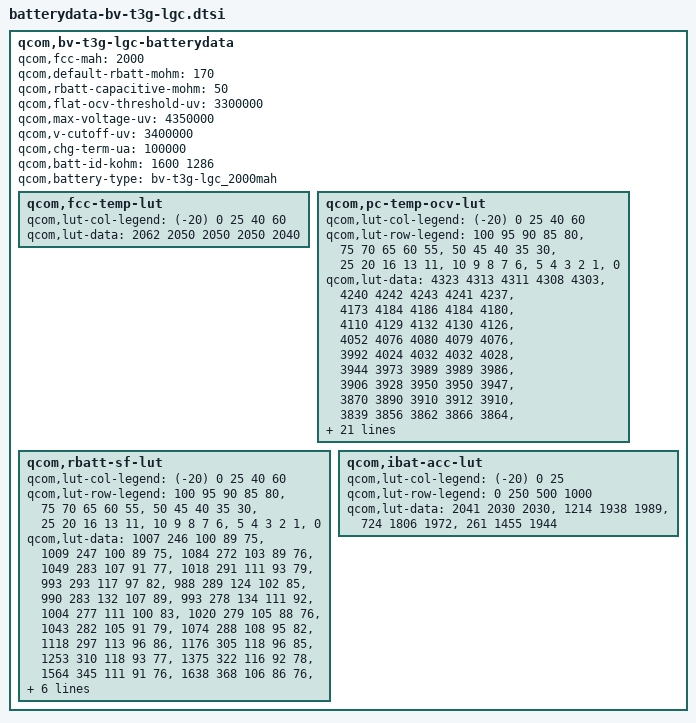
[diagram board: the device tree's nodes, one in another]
/* Copyright (c) 2013-2014, The Linux Foundation. All rights reserved.
 *
 * This program is free software; you can redistribute it and/or modify
 * it under the terms of the GNU General Public License version 2 and
 * only version 2 as published by the Free Software Foundation.
 *
 * This program is distributed in the hope that it will be useful,
 * but WITHOUT ANY WARRANTY; without even the implied warranty of
 * MERCHANTABILITY or FITNESS FOR A PARTICULAR PURPOSE.  See the
 * GNU General Public License for more details.
 */

qcom,bv-t3g-lgc-batterydata {
	qcom,fcc-mah = <2000>;
	qcom,default-rbatt-mohm = <170>;
	qcom,rbatt-capacitive-mohm = <50>;
	qcom,flat-ocv-threshold-uv = <3300000>;
	qcom,max-voltage-uv = <4350000>;
	qcom,v-cutoff-uv = <3400000>;
	qcom,chg-term-ua = <100000>;
	qcom,batt-id-kohm = <1600 1286>;
	qcom,battery-type = "bv-t3g-lgc_2000mah";

	qcom,fcc-temp-lut {
		qcom,lut-col-legend = <(-20) 0 25 40 60>;
		qcom,lut-data = <2062 2050 2050 2050 2040>;
	};

	qcom,pc-temp-ocv-lut {
		qcom,lut-col-legend = <(-20) 0 25 40 60>;
		qcom,lut-row-legend = <100 95 90 85 80>,
				<75 70 65 60 55>,
				<50 45 40 35 30>,
				<25 20 16 13 11>,
				<10 9 8 7 6>,
				<5 4 3 2 1>,
				<0>;
		qcom,lut-data = <4323 4313 4311 4308 4303>,
				<4240 4242 4243 4241 4237>,
				<4173 4184 4186 4184 4180>,
				<4110 4129 4132 4130 4126>,
				<4052 4076 4080 4079 4076>,
				<3992 4024 4032 4032 4028>,
				<3944 3973 3989 3989 3986>,
				<3906 3928 3950 3950 3947>,
				<3870 3890 3910 3912 3910>,
				<3839 3856 3862 3866 3864>,
				<3813 3829 3830 3830 3830>,
				<3790 3806 3808 3808 3808>,
				<3772 3786 3790 3791 3790>,
				<3754 3770 3778 3776 3774>,
				<3737 3754 3766 3762 3757>,
				<3719 3738 3754 3745 3732>,
				<3698 3721 3732 3722 3708>,
				<3676 3708 3700 3692 3678>,
				<3658 3696 3680 3672 3661>,
				<3641 3686 3678 3670 3658>,
				<3630 3682 3676 3668 3657>,
				<3619 3676 3674 3666 3655>,
				<3606 3670 3670 3664 3652>,
				<3588 3660 3666 3658 3646>,
				<3569 3643 3652 3642 3625>,
				<3543 3613 3618 3606 3586>,
				<3508 3568 3568 3554 3535>,
				<3458 3506 3500 3486 3470>,
				<3375 3419 3412 3398 3384>,
				<3249 3286 3278 3260 3245>,
				<3000 3000 3000 3000 3000>;
	};

	qcom,rbatt-sf-lut {
		qcom,lut-col-legend = <(-20) 0 25 40 60>;
		qcom,lut-row-legend = <100 95 90 85 80>,
				<75 70 65 60 55>,
				<50 45 40 35 30>,
				<25 20 16 13 11>,
				<10 9 8 7 6>,
				<5 4 3 2 1>,
				<0>;
		qcom,lut-data = <1007 246 100 89 75>,
				<1009 247 100 89 75>,
				<1084 272 103 89 76>,
				<1049 283 107 91 77>,
				<1018 291 111 93 79>,
				<993 293 117 97 82>,
				<988 289 124 102 85>,
				<990 283 132 107 89>,
				<993 278 134 111 92>,
				<1004 277 111 100 83>,
				<1020 279 105 88 76>,
				<1043 282 105 91 79>,
				<1074 288 108 95 82>,
				<1118 297 113 96 86>,
				<1176 305 118 96 85>,
				<1253 310 118 93 77>,
				<1375 322 116 92 78>,
				<1564 345 111 91 76>,
				<1638 368 106 86 76>,
				<1824 373 109 92 78>,
				<1985 386 113 93 80>,
				<2184 404 118 96 82>,
				<2432 423 124 99 84>,
				<2755 443 129 101 84>,
				<3178 466 128 99 80>,
				<3732 493 123 95 80>,
				<4514 538 124 97 82>,
				<5633 617 128 101 86>,
				<7509 756 143 111 93>,
				<11531 1169 184 143 131>;
	};

	qcom,ibat-acc-lut {
		qcom,lut-col-legend = <(-20) 0 25>;
		qcom,lut-row-legend = <0 250 500 1000>;
		qcom,lut-data = <2041 2030 2030>,
				<1214 1938 1989>,
				<724 1806 1972>,
				<261 1455 1944>;
	};
};
